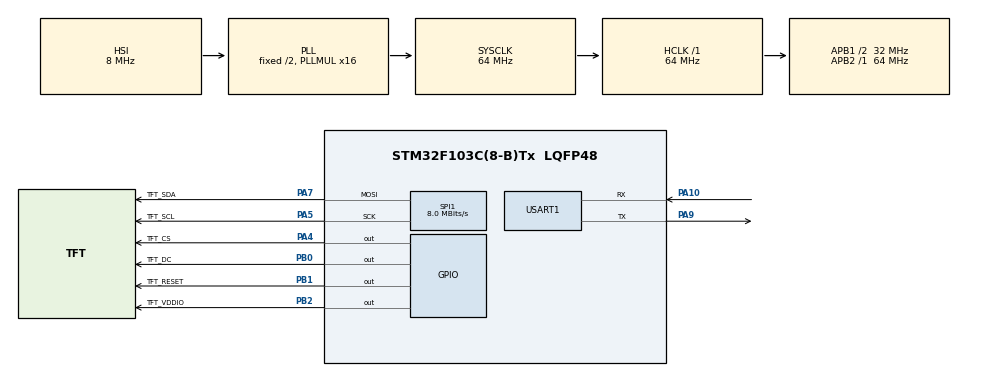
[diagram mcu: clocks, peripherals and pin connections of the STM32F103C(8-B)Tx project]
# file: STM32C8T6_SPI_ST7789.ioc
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Mcu.Family=STM32F1
Mcu.Name=STM32F103C(8-B)Tx
Mcu.Package=LQFP48
NVIC.PriorityGroup=NVIC_PRIORITYGROUP_4
PA10.Mode=Asynchronous
PA10.Signal=USART1_RX
PA4.GPIO_Label=TFT_CS
PA4.GPIO_PuPd=GPIO_NOPULL
PA4.PinState=GPIO_PIN_RESET
PA4.Signal=GPIO_Output
PA5.GPIO_Label=TFT_SCL
PA5.Mode=TX_Only_Simplex_Unidirect_Master
PA5.Signal=SPI1_SCK
PA7.GPIO_Label=TFT_SDA
PA7.Mode=TX_Only_Simplex_Unidirect_Master
PA7.Signal=SPI1_MOSI
PA9.Mode=Asynchronous
PA9.Signal=USART1_TX
PB0.GPIO_Label=TFT_DC
PB0.Signal=GPIO_Output
PB1.GPIO_Label=TFT_RESET
PB1.Signal=GPIO_Output
PB2.GPIO_Label=TFT_VDDIO
PB2.Signal=GPIO_Output
ProjectManager.HeapSize=0x200
ProjectManager.StackSize=0x400
ProjectManager.TargetToolchain=MDK-ARM V5.32
RCC.AHBFreq_Value=64000000
RCC.APB1CLKDivider=RCC_HCLK_DIV2
RCC.APB1Freq_Value=32000000
RCC.APB1TimFreq_Value=64000000
RCC.APB2Freq_Value=64000000
RCC.APB2TimFreq_Value=64000000
RCC.HCLKFreq_Value=64000000
RCC.PLLMUL=RCC_PLL_MUL16
RCC.SYSCLKFreq_VALUE=64000000
RCC.SYSCLKSource=RCC_SYSCLKSOURCE_PLLCLK
RCC.USBFreq_Value=64000000
SPI1.BaudRatePrescaler=SPI_BAUDRATEPRESCALER_8
SPI1.CalculateBaudRate=8.0 MBits/s
SPI1.Direction=SPI_DIRECTION_2LINES
SPI1.Mode=SPI_MODE_MASTER
SPI1.VirtualType=VM_MASTER
USART1.VirtualMode=VM_ASYNC
VP_SYS_VS_ND.Mode=No_Debug
board=custom

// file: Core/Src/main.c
/* USER CODE BEGIN Header */
/**
  ******************************************************************************
  * @file           : main.c
  * @brief          : Main program body
  ******************************************************************************
  * @attention
  *
  * Copyright (c) 2023 STMicroelectronics.
  * All rights reserved.
  *
  * This software is licensed under terms that can be found in the LICENSE file
  * in the root directory of this software component.
  * If no LICENSE file comes with this software, it is provided AS-IS.
  *
  ******************************************************************************
  */
/* USER CODE END Header */
#include "main.h"
#include "spi.h"
#include "usart.h"
#include "gpio.h"

/* USER CODE BEGIN Includes */
#include "lcd.h"
#include "lcd_init.h"
/* USER CODE END Includes */

/* USER CODE BEGIN PTD */
/* 函数指针重命名 主要是用于跳转 */

typedef  void (*pFunction)(void);

/* app起始执行地址 */

#define APPLICATION_ADDRESS   (uint32_t)0x08007000

/* 跳转函数 */

pFunction Jump_To_Application;

/* 跳转地址,中间变量作用 */

uint32_t JumpAddress;

/* 主流STM32芯片的SRAM地址范围都是从 0x2000 0000处开始。 128 Kbytes 的 SRAM

28 Kbytes的SRAM 地址范围是 0x2000 0000  --0x2001 FFFF;

所以 SP & 0x2FFE 0000 == 0x2000 0000，意味着如果超出128sram 就肯定是不正确的,所以检查17之后的位

同理,不同大小的sram    0x2FFE0000是需要改变的

*/
/* USER CODE END PTD */

void SystemClock_Config(void);

int main(void)
{

  /* MCU Configuration--------------------------------------------------------*/

  /* Reset of all peripherals, Initializes the Flash interface and the Systick. */
  HAL_Init();

  /* Configure the system clock */
  SystemClock_Config();

  /* Initialize all configured peripherals */
  MX_GPIO_Init();
  MX_USART1_UART_Init();
  MX_SPI1_Init();
  /* USER CODE BEGIN 2 */
	HAL_Delay(100);

	LCD_Init();//LCD初始化
	LCD_Fill(0,0,LCD_W,LCD_H,WHITE);

  /* USER DCODE END 2 */

  /* Infinite loop */
  while (1)
  {

  }
}

void SystemClock_Config(void)
{
  RCC_OscInitTypeDef RCC_OscInitStruct = {0};
  RCC_ClkInitTypeDef RCC_ClkInitStruct = {0};

  /** Initializes the RCC Oscillators according to the specified parameters
  * in the RCC_OscInitTypeDef structure.
  */
  RCC_OscInitStruct.OscillatorType = RCC_OSCILLATORTYPE_HSI;
  RCC_OscInitStruct.HSIState = RCC_HSI_ON;
  RCC_OscInitStruct.HSICalibrationValue = RCC_HSICALIBRATION_DEFAULT;
  RCC_OscInitStruct.PLL.PLLState = RCC_PLL_ON;
  RCC_OscInitStruct.PLL.PLLSource = RCC_PLLSOURCE_HSI_DIV2;
  RCC_OscInitStruct.PLL.PLLMUL = RCC_PLL_MUL16;
  if (HAL_RCC_OscConfig(&RCC_OscInitStruct) != HAL_OK)
  {
    Error_Handler();
  }

  /** Initializes the CPU, AHB and APB buses clocks
  */
  RCC_ClkInitStruct.ClockType = RCC_CLOCKTYPE_HCLK|RCC_CLOCKTYPE_SYSCLK
                              |RCC_CLOCKTYPE_PCLK1|RCC_CLOCKTYPE_PCLK2;
  RCC_ClkInitStruct.SYSCLKSource = RCC_SYSCLKSOURCE_PLLCLK;
  RCC_ClkInitStruct.AHBCLKDivider = RCC_SYSCLK_DIV1;
  RCC_ClkInitStruct.APB1CLKDivider = RCC_HCLK_DIV2;
  RCC_ClkInitStruct.APB2CLKDivider = RCC_HCLK_DIV1;

  if (HAL_RCC_ClockConfig(&RCC_ClkInitStruct, FLASH_LATENCY_2) != HAL_OK)
  {
    Error_Handler();
  }
}

void Error_Handler(void)
{
  __disable_irq();
  while (1)
  {
  }
}
